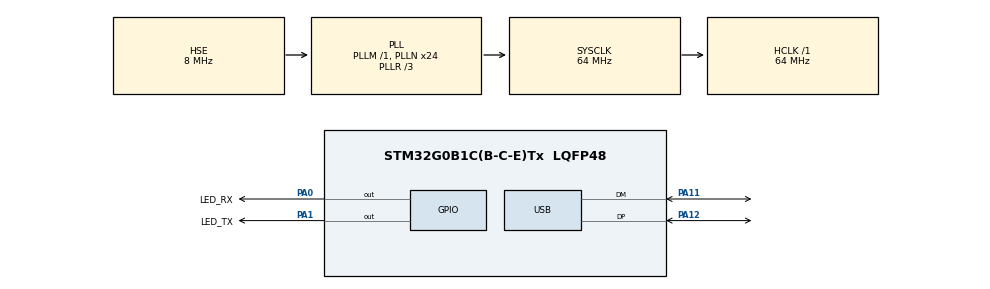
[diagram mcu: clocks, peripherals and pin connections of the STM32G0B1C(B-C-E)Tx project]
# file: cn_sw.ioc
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FREERTOS.Tasks01=defaultTask,0,128,StartDefaultTask,Default,NULL,Dynamic,NULL,NULL;LED_Task,-3,128,Start_LED_Task,Default,NULL,Dynamic,NULL,NULL
Mcu.Family=STM32G0
Mcu.Name=STM32G0B1C(B-C-E)Tx
Mcu.Package=LQFP48
NVIC.TIM1_BRK_UP_TRG_COM_IRQn=true\:3\:0\:false\:false\:true\:false\:false\:true\:true
NVIC.TimeBase=TIM1_BRK_UP_TRG_COM_IRQn
NVIC.TimeBaseIP=TIM1
NVIC.USB_UCPD1_2_IRQn=true\:3\:0\:false\:false\:true\:true\:true\:true\:true
PA0.GPIO_Label=LED_RX
PA0.GPIO_ModeDefaultOutputPP=GPIO_MODE_OUTPUT_OD
PA0.GPIO_PuPd=GPIO_PULLUP
PA0.PinState=GPIO_PIN_SET
PA0.Signal=GPIO_Output
PA1.GPIO_Label=LED_TX
PA1.GPIO_ModeDefaultOutputPP=GPIO_MODE_OUTPUT_OD
PA1.GPIO_PuPd=GPIO_PULLUP
PA1.GPIO_Speed=GPIO_SPEED_FREQ_LOW
PA1.PinState=GPIO_PIN_RESET
PA1.Signal=GPIO_Output
PA11\ [PA9].Mode=Device
PA11\ [PA9].Signal=USB_DM
PA12\ [PA10].Mode=Device
PA12\ [PA10].Signal=USB_DP
PF0-OSC_IN\ (PF0).Mode=HSE-External-Oscillator
PF0-OSC_IN\ (PF0).Signal=RCC_OSC_IN
PF1-OSC_OUT\ (PF1).Mode=HSE-External-Oscillator
PF1-OSC_OUT\ (PF1).Signal=RCC_OSC_OUT
ProjectManager.HeapSize=0x200
ProjectManager.StackSize=0x400
ProjectManager.TargetToolchain=Makefile
RCC.ADCFreq_Value=64000000
RCC.AHBFreq_Value=64000000
RCC.CortexFreq_Value=64000000
RCC.EXTERNAL_CLOCK_VALUE=48000
RCC.HCLKFreq_Value=64000000
RCC.HSE_VALUE=8000000
RCC.HSI48_VALUE=48000000
RCC.HSI_VALUE=16000000
RCC.LSE_VALUE=32768
RCC.PLLN=24
RCC.PLLQ=RCC_PLLQ_DIV4
RCC.PLLR=RCC_PLLR_DIV3
RCC.PLLSourceVirtual=RCC_PLLSOURCE_HSE
RCC.SYSCLKFreq_VALUE=64000000
RCC.SYSCLKSource=RCC_SYSCLKSOURCE_PLLCLK
RCC.USBCLockSelection=RCC_USBCLKSOURCE_PLL
RCC.USBFreq_Value=48000000
RCC.VCOOutputFreq_Value=192000000
VP_FREERTOS_VS_CMSIS_V1.Mode=CMSIS_V1
VP_SYS_VS_tim1.Mode=TIM1
board=custom

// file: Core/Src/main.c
/* USER CODE BEGIN Header */
/**
  ******************************************************************************
  * @file           : main.c
  * @brief          : Main program body
  ******************************************************************************
  * @attention
  *
  * Copyright (c) 2023 STMicroelectronics.
  * All rights reserved.
  *
  * This software is licensed under terms that can be found in the LICENSE file
  * in the root directory of this software component.
  * If no LICENSE file comes with this software, it is provided AS-IS.
  *
  ******************************************************************************
  */
/* USER CODE END Header */
#include "main.h"
#include "cmsis_os.h"
#include "usb_drd_fs.h"
#include "gpio.h"

void SystemClock_Config(void);
void MX_FREERTOS_Init(void);

int main(void)
{

  /* MCU Configuration--------------------------------------------------------*/

  /* Reset of all peripherals, Initializes the Flash interface and the Systick. */
  HAL_Init();

  /* Configure the system clock */
  SystemClock_Config();

  /* Initialize all configured peripherals */
  MX_GPIO_Init();
  MX_USB_DRD_FS_PCD_Init();

  /* Call init function for freertos objects (in freertos.c) */
  MX_FREERTOS_Init();

  /* Start scheduler */
  osKernelStart();

  /* We should never get here as control is now taken by the scheduler */
  /* Infinite loop */
  while (1)
  {

  }
}

void SystemClock_Config(void)
{
  RCC_OscInitTypeDef RCC_OscInitStruct = {0};
  RCC_ClkInitTypeDef RCC_ClkInitStruct = {0};

  /** Configure the main internal regulator output voltage
  */
  HAL_PWREx_ControlVoltageScaling(PWR_REGULATOR_VOLTAGE_SCALE1);

  /** Initializes the RCC Oscillators according to the specified parameters
  * in the RCC_OscInitTypeDef structure.
  */
  RCC_OscInitStruct.OscillatorType = RCC_OSCILLATORTYPE_HSE;
  RCC_OscInitStruct.HSEState = RCC_HSE_ON;
  RCC_OscInitStruct.PLL.PLLState = RCC_PLL_ON;
  RCC_OscInitStruct.PLL.PLLSource = RCC_PLLSOURCE_HSE;
  RCC_OscInitStruct.PLL.PLLM = RCC_PLLM_DIV1;
  RCC_OscInitStruct.PLL.PLLN = 24;
  RCC_OscInitStruct.PLL.PLLP = RCC_PLLP_DIV2;
  RCC_OscInitStruct.PLL.PLLQ = RCC_PLLQ_DIV4;
  RCC_OscInitStruct.PLL.PLLR = RCC_PLLR_DIV3;
  if (HAL_RCC_OscConfig(&RCC_OscInitStruct) != HAL_OK)
  {
    Error_Handler();
  }

  /** Initializes the CPU, AHB and APB buses clocks
  */
  RCC_ClkInitStruct.ClockType = RCC_CLOCKTYPE_HCLK|RCC_CLOCKTYPE_SYSCLK
                              |RCC_CLOCKTYPE_PCLK1;
  RCC_ClkInitStruct.SYSCLKSource = RCC_SYSCLKSOURCE_PLLCLK;
  RCC_ClkInitStruct.AHBCLKDivider = RCC_SYSCLK_DIV1;
  RCC_ClkInitStruct.APB1CLKDivider = RCC_HCLK_DIV1;

  if (HAL_RCC_ClockConfig(&RCC_ClkInitStruct, FLASH_LATENCY_2) != HAL_OK)
  {
    Error_Handler();
  }
}

void HAL_TIM_PeriodElapsedCallback(TIM_HandleTypeDef *htim)
{
  if (htim->Instance == TIM1) {
    HAL_IncTick();
  }
}

void Error_Handler(void)
{
  __disable_irq();
  while (1)
  {
  }
}

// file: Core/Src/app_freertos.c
/* USER CODE BEGIN Header */
/**
  ******************************************************************************
  * File Name          : app_freertos.c
  * Description        : Code for freertos applications
  ******************************************************************************
  * @attention
  *
  * Copyright (c) 2023 STMicroelectronics.
  * All rights reserved.
  *
  * This software is licensed under terms that can be found in the LICENSE file
  * in the root directory of this software component.
  * If no LICENSE file comes with this software, it is provided AS-IS.
  *
  ******************************************************************************
  */
/* USER CODE END Header */

#include "FreeRTOS.h"
#include "task.h"
#include "main.h"
#include "cmsis_os.h"

osThreadId defaultTaskHandle;
osThreadId LED_TaskHandle;

void StartDefaultTask(void const * argument);
void Start_LED_Task(void const * argument);

void MX_FREERTOS_Init(void); /* (MISRA C 2004 rule 8.1) */

void MX_FREERTOS_Init(void) {

  /* Create the thread(s) */
  /* definition and creation of defaultTask */
  osThreadDef(defaultTask, StartDefaultTask, osPriorityNormal, 0, 128);
  defaultTaskHandle = osThreadCreate(osThread(defaultTask), NULL);

  /* definition and creation of LED_Task */
  osThreadDef(LED_Task, Start_LED_Task, osPriorityIdle, 0, 128);
  LED_TaskHandle = osThreadCreate(osThread(LED_Task), NULL);

}

void StartDefaultTask(void const * argument)
{
  for(;;)
  {
    osDelay(1);
  }
}

void Start_LED_Task(void const * argument)
{
  /* USER CODE BEGIN Start_LED_Task */
  /* Infinite loop */
  for(;;)
  {
    HAL_GPIO_TogglePin(LED_RX_GPIO_Port, LED_RX_Pin);
    HAL_GPIO_TogglePin(LED_TX_GPIO_Port, LED_TX_Pin);
    osDelay(500);
  }
  /* USER CODE END Start_LED_Task */
}
